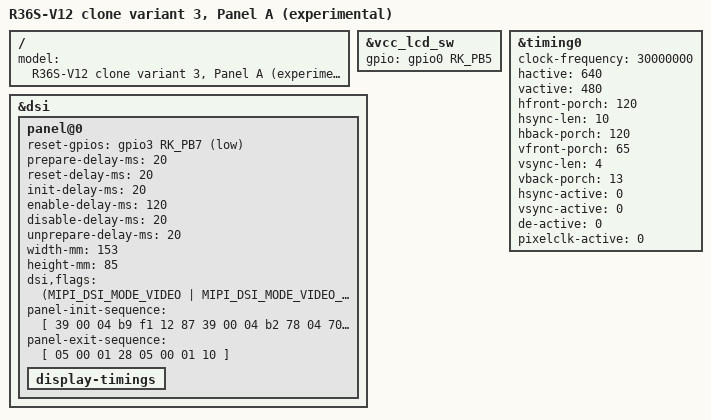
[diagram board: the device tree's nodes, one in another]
// SPDX-License-Identifier: (GPL-2.0+ OR MIT)
/*
 * EXPERIMENTAL - keep a copy of the files you replace so you can go back.
 * Tested on a V12 clone by an andr36oid user (2026-10-12): picture works. Its
 * stock card DTB described G80 wiring, which did not give a picture.
 *
 * EE clone "R36S-V12 2023-08-18 Variant 3 Panel A": wiring as Variant 3,
 * with "Panel A" (23-command init sequence).
 * Source: dArkOSRE port by southoz (dArkOSRE-R36, clone/R36S-V12 ... Variant 3 Panel A).
 */

/dts-v1/;
#include "rk3326-r36s-clone-ee.dtsi"

/ {
	model = "R36S-V12 clone variant 3, Panel A (experimental)";
};

&vcc_lcd_sw {
	gpio = <&gpio0 RK_PB5 GPIO_ACTIVE_HIGH>;
};

&dsi {
	panel@0 {
		reset-gpios = <&gpio3 RK_PB7 GPIO_ACTIVE_LOW>;
	};
};

&dsi {
	panel@0 {
		prepare-delay-ms = <20>;
		reset-delay-ms = <20>;
		init-delay-ms = <20>;
		enable-delay-ms = <120>;
		disable-delay-ms = <20>;
		unprepare-delay-ms = <20>;
		width-mm = <153>;
		height-mm = <85>;
		dsi,flags = <(MIPI_DSI_MODE_VIDEO |
		      MIPI_DSI_MODE_VIDEO_BURST |
		      MIPI_DSI_MODE_EOT_PACKET |
		      MIPI_DSI_MODE_LPM)>;
		panel-init-sequence = [
			39 00 04 b9 f1 12 87
			39 00 04 b2 78 04 70
			39 00 0b b3 10 10 fc fc 03 ff 00 00 00 00
			15 00 02 b4 80
			15 00 03 b5 0f 0f
			15 00 03 b6 70 70
			39 00 05 b8 26 22 f0 13
			39 00 1c ba 33 81 05 f9 0e 0e 20 00 00 00 00 00 00 00 44 25 00 91 0a 00 00 01 4f 01 00 00 37
			15 00 02 bc 47
			39 00 06 bf 02 11 00 80 04
			39 00 0a c0 73 73 50 50 00 00 12 73 00
			39 00 12 c1 73 00 32 32 77 f4 77 77 cc cc ff ff 11 11 00 00 32
			39 00 0d c7 b8 00 0a 10 01 09 00 00 ed c5 00 a5
			39 00 05 c8 10 40 1e 03
			15 00 02 cc 0b
			39 00 23 e0 00 05 09 29 3c 3f 3b 37 05 0a 0c 10 13 10 13 12 1a 00 05 09 29 3c 3f 3b 37 05 0a 0c 10 13 10 13 12 1a
			39 00 08 e1 11 11 91 00 00 00 00
			39 00 0f e3 07 07 0b 0b 0b 0b 00 00 00 00 ff 04 c0 10
			39 00 40 e9 c8 10 02 00 00 b0 b1 11 31 23 28 80 b0 b1 27 08 00 04 02 00 00 00 00 04 02 00 00 00 88 88 ba 60 24 08 88 88 88 88 88 88 88 ba 71 35 18 88 88 88 88 88 00 00 00 01 00 00 00 00 00 00 00 00 00
			39 00 3e ea 97 0a 82 02 03 07 00 00 00 00 00 00 81 88 ba 17 53 88 88 88 88 88 88 80 88 ba 06 42 88 88 88 88 88 88 23 00 00 02 a5 00 00 00 00 00 00 00 00 00 00 00 00 00 00 00 00 00 00 00 00 00 00
			39 00 04 ef ff ff 01
			05 c8 01 11
			05 10 01 29
		];
		panel-exit-sequence = [
			05 00 01 28
			05 00 01 10
		];
		display-timings {
			/* one mode only: the R36S alternates below do not fit this panel */
			/delete-node/ timing1;
			/delete-node/ timing2;
		};
	};
};

&timing0 {
	clock-frequency = <30000000>;
	hactive = <640>;
	vactive = <480>;
	hfront-porch = <120>;
	hsync-len = <10>;
	hback-porch = <120>;
	vfront-porch = <65>;	/* was 17: 65.6 Hz; 59.98 Hz, same pixel clock */
	vsync-len = <4>;
	vback-porch = <13>;
	hsync-active = <0>;
	vsync-active = <0>;
	de-active = <0>;
	pixelclk-active = <0>;
};
